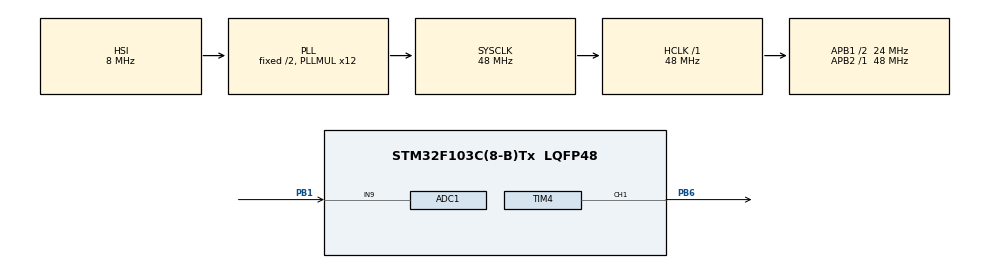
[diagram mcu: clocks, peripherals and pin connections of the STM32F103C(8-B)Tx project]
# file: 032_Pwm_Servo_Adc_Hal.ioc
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ADC1.Channel-2\#ChannelRegularConversion=ADC_CHANNEL_9
ADC1.ContinuousConvMode=ENABLE
ADC1.NbrOfConversionFlag=1
ADC1.Rank-2\#ChannelRegularConversion=1
ADC1.SamplingTime-2\#ChannelRegularConversion=ADC_SAMPLETIME_71CYCLES_5
ADC1.master=1
Mcu.Family=STM32F1
Mcu.Name=STM32F103C(8-B)Tx
Mcu.Package=LQFP48
NVIC.PriorityGroup=NVIC_PRIORITYGROUP_4
PA13.Mode=Serial_Wire
PA13.Signal=SYS_JTMS-SWDIO
PA14.Mode=Serial_Wire
PA14.Signal=SYS_JTCK-SWCLK
PB1.Signal=ADCx_IN9
PB6.Signal=S_TIM4_CH1
ProjectManager.HeapSize=0x200
ProjectManager.StackSize=0x400
ProjectManager.TargetToolchain=STM32CubeIDE
RCC.ADCPresc=RCC_ADCPCLK2_DIV4
RCC.AHBFreq_Value=48000000
RCC.APB1CLKDivider=RCC_HCLK_DIV2
RCC.APB1Freq_Value=24000000
RCC.APB1TimFreq_Value=48000000
RCC.APB2Freq_Value=48000000
RCC.APB2TimFreq_Value=48000000
RCC.HCLKFreq_Value=48000000
RCC.PLLMUL=RCC_PLL_MUL12
RCC.SYSCLKFreq_VALUE=48000000
RCC.SYSCLKSource=RCC_SYSCLKSOURCE_PLLCLK
RCC.USBFreq_Value=48000000
SH.ADCx_IN9.0=ADC1_IN9,IN9
SH.S_TIM4_CH1.0=TIM4_CH1,PWM Generation1 CH1
TIM4.Channel-PWM\ Generation1\ CH1=TIM_CHANNEL_1
TIM4.Period=19999
TIM4.Prescaler=47
board=custom

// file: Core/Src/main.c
/* USER CODE BEGIN Header */
/**
  ******************************************************************************
  * @file           : main.c
  * @brief          : Main program body
  ******************************************************************************
  * @attention
  *
  * Copyright (c) 2024 STMicroelectronics.
  * All rights reserved.
  *
  * This software is licensed under terms that can be found in the LICENSE file
  * in the root directory of this software component.
  * If no LICENSE file comes with this software, it is provided AS-IS.
  *
  ******************************************************************************
  */
/* USER CODE END Header */
#include "main.h"

ADC_HandleTypeDef hadc1;

TIM_HandleTypeDef htim4;

/* USER CODE BEGIN PV */

uint16_t adc_value;
uint32_t pulse;

/* USER CODE END PV */

void SystemClock_Config(void);
static void MX_GPIO_Init(void);
static void MX_ADC1_Init(void);
static void MX_TIM4_Init(void);
/* USER CODE BEGIN PFP */
void Read_Adc();
uint32_t map(int In, int In_min ,int In_max, int Out_min, int Out_max);

/* USER CODE END PFP */

/* USER CODE BEGIN 0 */

/*
 * @brief read adc value from P0 channel 1
 * @param none
 * @retval none
 */
void Read_Adc(){
	HAL_ADC_Start(&hadc1);

	if(HAL_ADC_PollForConversion(&hadc1, 100000) == HAL_OK){
		adc_value = HAL_ADC_GetValue(&hadc1);
	}

	HAL_ADC_Stop(&hadc1);
}

/*
 * @brief map funct. to scale adc value for pwm generator
 * @param In: Adc value given, In_min: adc min value, In_max: adc max value, out_min: pwm min value, out_max: pwm max value
 * @retval pulse: pwm value corrasponding to adc value In
 */

uint32_t map(int In, int In_min ,int In_max, int Out_min, int Out_max){
	return ((In-In_min) * (Out_max- Out_min) / (In_max - In_min) + Out_min);
}

/* USER CODE END 0 */

int main(void)
{

  /* MCU Configuration--------------------------------------------------------*/

  /* Reset of all peripherals, Initializes the Flash interface and the Systick. */
  HAL_Init();

  /* Configure the system clock */
  SystemClock_Config();

  /* Initialize all configured peripherals */
  MX_GPIO_Init();
  MX_ADC1_Init();
  MX_TIM4_Init();
  /* USER CODE BEGIN 2 */
  HAL_TIM_PWM_Start(&htim4, pulse);

  /* USER CODE END 2 */

  /* Infinite loop */
  while (1)
  {

    /* USER CODE BEGIN 3 */
	  Read_Adc();

	  pulse = map(adc_value, 0, 4095, 500, 2500);

	  __HAL_TIM_SET_COMPARE(&htim4,TIM_CHANNEL_1,pulse);
  }
  /* USER CODE END 3 */
}

void SystemClock_Config(void)
{
  RCC_OscInitTypeDef RCC_OscInitStruct = {0};
  RCC_ClkInitTypeDef RCC_ClkInitStruct = {0};
  RCC_PeriphCLKInitTypeDef PeriphClkInit = {0};

  /** Initializes the RCC Oscillators according to the specified parameters
  * in the RCC_OscInitTypeDef structure.
  */
  RCC_OscInitStruct.OscillatorType = RCC_OSCILLATORTYPE_HSI;
  RCC_OscInitStruct.HSIState = RCC_HSI_ON;
  RCC_OscInitStruct.HSICalibrationValue = RCC_HSICALIBRATION_DEFAULT;
  RCC_OscInitStruct.PLL.PLLState = RCC_PLL_ON;
  RCC_OscInitStruct.PLL.PLLSource = RCC_PLLSOURCE_HSI_DIV2;
  RCC_OscInitStruct.PLL.PLLMUL = RCC_PLL_MUL12;
  if (HAL_RCC_OscConfig(&RCC_OscInitStruct) != HAL_OK)
  {
    Error_Handler();
  }

  /** Initializes the CPU, AHB and APB buses clocks
  */
  RCC_ClkInitStruct.ClockType = RCC_CLOCKTYPE_HCLK|RCC_CLOCKTYPE_SYSCLK
                              |RCC_CLOCKTYPE_PCLK1|RCC_CLOCKTYPE_PCLK2;
  RCC_ClkInitStruct.SYSCLKSource = RCC_SYSCLKSOURCE_PLLCLK;
  RCC_ClkInitStruct.AHBCLKDivider = RCC_SYSCLK_DIV1;
  RCC_ClkInitStruct.APB1CLKDivider = RCC_HCLK_DIV2;
  RCC_ClkInitStruct.APB2CLKDivider = RCC_HCLK_DIV1;

  if (HAL_RCC_ClockConfig(&RCC_ClkInitStruct, FLASH_LATENCY_1) != HAL_OK)
  {
    Error_Handler();
  }
  PeriphClkInit.PeriphClockSelection = RCC_PERIPHCLK_ADC;
  PeriphClkInit.AdcClockSelection = RCC_ADCPCLK2_DIV4;
  if (HAL_RCCEx_PeriphCLKConfig(&PeriphClkInit) != HAL_OK)
  {
    Error_Handler();
  }
}

static void MX_ADC1_Init(void)
{

  ADC_ChannelConfTypeDef sConfig = {0};

  /** Common config
  */
  hadc1.Instance = ADC1;
  hadc1.Init.ScanConvMode = ADC_SCAN_DISABLE;
  hadc1.Init.ContinuousConvMode = ENABLE;
  hadc1.Init.DiscontinuousConvMode = DISABLE;
  hadc1.Init.ExternalTrigConv = ADC_SOFTWARE_START;
  hadc1.Init.DataAlign = ADC_DATAALIGN_RIGHT;
  hadc1.Init.NbrOfConversion = 1;
  if (HAL_ADC_Init(&hadc1) != HAL_OK)
  {
    Error_Handler();
  }

  /** Configure Regular Channel
  */
  sConfig.Channel = ADC_CHANNEL_9;
  sConfig.Rank = ADC_REGULAR_RANK_1;
  sConfig.SamplingTime = ADC_SAMPLETIME_71CYCLES_5;
  if (HAL_ADC_ConfigChannel(&hadc1, &sConfig) != HAL_OK)
  {
    Error_Handler();
  }

}

static void MX_TIM4_Init(void)
{

  TIM_MasterConfigTypeDef sMasterConfig = {0};
  TIM_OC_InitTypeDef sConfigOC = {0};

  htim4.Instance = TIM4;
  htim4.Init.Prescaler = 47;
  htim4.Init.CounterMode = TIM_COUNTERMODE_UP;
  htim4.Init.Period = 19999;
  htim4.Init.ClockDivision = TIM_CLOCKDIVISION_DIV1;
  htim4.Init.AutoReloadPreload = TIM_AUTORELOAD_PRELOAD_DISABLE;
  if (HAL_TIM_PWM_Init(&htim4) != HAL_OK)
  {
    Error_Handler();
  }
  sMasterConfig.MasterOutputTrigger = TIM_TRGO_RESET;
  sMasterConfig.MasterSlaveMode = TIM_MASTERSLAVEMODE_DISABLE;
  if (HAL_TIMEx_MasterConfigSynchronization(&htim4, &sMasterConfig) != HAL_OK)
  {
    Error_Handler();
  }
  sConfigOC.OCMode = TIM_OCMODE_PWM1;
  sConfigOC.Pulse = 0;
  sConfigOC.OCPolarity = TIM_OCPOLARITY_HIGH;
  sConfigOC.OCFastMode = TIM_OCFAST_DISABLE;
  if (HAL_TIM_PWM_ConfigChannel(&htim4, &sConfigOC, TIM_CHANNEL_1) != HAL_OK)
  {
    Error_Handler();
  }
  HAL_TIM_MspPostInit(&htim4);

}

static void MX_GPIO_Init(void)
{

  /* GPIO Ports Clock Enable */
  __HAL_RCC_GPIOB_CLK_ENABLE();
  __HAL_RCC_GPIOA_CLK_ENABLE();

}

void Error_Handler(void)
{
  __disable_irq();
  while (1)
  {
  }
}
